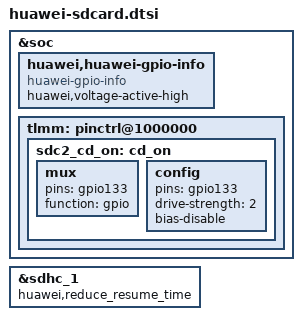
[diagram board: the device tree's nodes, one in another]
&soc {
	huawei,huawei-gpio-info {
		compatible = "huawei-gpio-info";
		huawei,voltage-active-high;
	};
};

&soc {
	tlmm: pinctrl@1000000 {
	sdc2_cd_on: cd_on {
			mux {
				pins = "gpio133";
				function = "gpio";
			};

			config {
				pins = "gpio133";
				drive-strength = <2>;
				bias-disable;
			};
		};
	};
};

/* emmc reduce resume time*/
&sdhc_1 {

		huawei,reduce_resume_time;
};
